# SF32LB52x register map
File version: 1.0
CPU: CM33 r0p1, little endian, MPU, FPU, 3 interrupt priority bits
Registers are 32-bit, read-write, reset 0x0 unless marked. A register's access mark holds for its fields unless they carry their own. Offsets are from the block's base; lines under a group give offsets from that group; [hi:lo] are bit positions; {n}, {i} and the like mark numbered series; 'fields as' and 'values as' point back to an identical list; <NAME> marks a mode.

## Memory map
0x40000000 LPSYS_RCC size 0x1000
0x40001000 DMAC2 size 0x1000
0x40003000 LPSYS_PINMUX size 0x1000
0x40005000 USART4 size 0x1000 — USART
0x40006000 USART5 size 0x1000 — USART
0x40009000 BTIM3 size 0x1000 — Basic Timer
0x4000A000 BTIM4 size 0x1000 — Basic Timer
0x4000B000 WDT2 size 0x1000 — Watchdog 2
0x4000C000 PTC2 size 0x1000
0x4000F000 LPSYS_CFG size 0x1000
0x40040000 LPSYS_AON size 0x1000
0x40042000 LPTIM3 size 0x1000 — Low Power Timer
0x40085000 CRC2 size 0x1000 — Cyclic Redundancy Check
0x50000000 HPSYS_RCC size 0x1000
0x50001000 EXTDMA size 0x1000
0x50003000 HPSYS_PINMUX size 0x1000
0x50004000 ATIM1 size 0x1000 — Advanced Timer
0x50005000 AUDPRC size 0x1000 — Audio Process Controller
0x50006000 EZIP1 size 0x1000
0x50007000 EPIC size 0x1000
0x50008000 LCDC1 size 0x1000 — LCD Controller
0x50009000 I2S1 size 0x1000 — Inter IC Sound
0x5000B000 HPSYS_CFG size 0x1000
0x5000C000 EFUSEC size 0x1000 — efuse control
0x5000D000 AES size 0x1000
0x5000F000 TRNG size 0x1000 — True Random Number Generator
0x50041000 MPI1 size 0x1000 — Memory Peripheral Interface
0x50042000 MPI2 size 0x1000 — Memory Peripheral Interface
0x50045000 SDMMC1 size 0x1000
0x50048000 CRC1 size 0x1000 — Cyclic Redundancy Check
0x50080000 PTC1 size 0x1000
0x50081000 DMAC1 size 0x1000
0x50084000 USART1 size 0x1000 — USART
0x50085000 USART2 size 0x1000 — USART
0x50086000 USART3 size 0x1000 — USART
0x50087000 GPADC size 0x1000
0x50088000 AUDCODEC size 0x1000
0x50089000 TSEN size 0x1000
0x50090000 GPTIM1 size 0x1000 — General Purpose Timer
0x50092000 BTIM1 size 0x1000 — Basic Timer
0x50094000 WDT1 size 0x1000 — Watchdog 1
0x50095000 SPI1 size 0x1000 — SPI
0x50096000 SPI2 size 0x1000 — SPI
0x5009A000 PDM1 size 0x1000 — Pulse Density Modulation
0x5009C000 I2C1 size 0x1000 — I2C
0x5009D000 I2C2 size 0x1000 — I2C
0x5009E000 I2C3 size 0x1000 — I2C
0x5009F000 I2C4 size 0x1000 — I2C
0x500A0000 HPSYS_GPIO size 0x1000
0x500B0000 GPTIM2 size 0x1000 — General Purpose Timer
0x500B1000 BTIM2 size 0x1000 — Basic Timer
0x500C0000 HPSYS_AON size 0x1000
0x500C1000 LPTIM1 size 0x1000 — Low Power Timer
0x500C2000 LPTIM2 size 0x1000 — Low Power Timer
0x500CA000 PMUC size 0x1000
0x500CC000 IWDT size 0x1000 — IWatchdog

## EXTDMA
Base 0x50001000
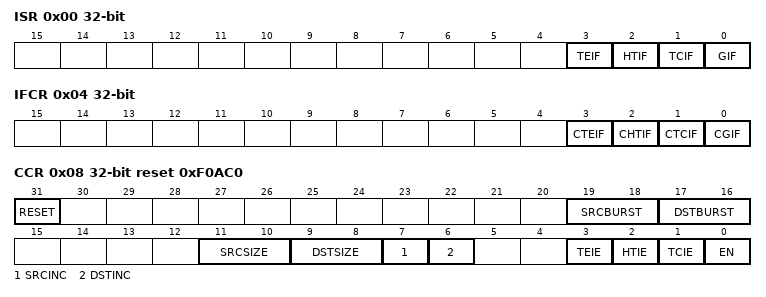
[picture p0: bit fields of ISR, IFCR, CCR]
0x00 ISR — interrupt status register
  [3] TEIF — TEIF, transfer error flag
  [2] HTIF — HTIF, half transfer flag
  [1] TCIF — TCIF, transfer complete flag
  [0] GIF — GIF, global interrupt flag
0x04 IFCR — interrupt clear register
  [3] CTEIF — CTEIF, transfer error flag clear
  [2] CHTIF — CHTIF, half transfer flag clear
  [1] CTCIF — CTCIF, transfer complete flag clear
  [0] CGIF — CGIF, global interrupt flag clear
0x08 CCR reset 0xF0AC0 — channel control register
  [31] RESET — Software reset, will clear extdma status. Active high. Will be cleared by HW automatically
  [19:18] SRCBURST — source burst transfer configuration 00: single transfer 01: INCR4 (incremental burst of 4 beats) 10: INCR8 (incremental burst of 8 beats) 11: INCR16 (incremental burst of 16 beats)
  [17:16] DSTBURST — destination burst transfer configuration 00: single transfer 01: INCR4 (incremental burst of 4 beats) 10: INCR8 (incremental burst of 8 beats) 11: INCR16 (incremental burst of 16 beats)
  [11:10] SRCSIZE — source size Defines the data size of each DMA transfer to the source memory. Should be fixed to 10 (32 bits), word access allowed only.
  [9:8] DSTSIZE — destination size Defines the data size of each DMA transfer to the destination memory. Should be fixed to 10 (32 bits), word access allowed only.
  [7] SRCINC — source increment mode Defines the increment mode for each DMA transfer to the source memory. 0: disabled 1: enabled
  [6] DSTINC — destination increment mode Defines the increment mode for each DMA transfer to the destination memory. 0: disabled 1: enabled
  [3] TEIE — transfer error interrupt enable 0: disabled 1: enabled
  [2] HTIE — half transfer interrupt enable 0: disabled 1: enabled
  [1] TCIE — transfer complete interrupt enable 0: disabled 1: enabled
  [0] EN — extdma enable. Will be cleared if ccr_reset is written
0x0C CNDTR — number of data register
  [19:0] NDT — number of data to transfer (0 to 2^20 - 1) This field is updated by hardware when the channel is enabled: It is decremented after each transfer, indicating the remaining amount of data items to transfer. It is kept at zero when the programmed amount of data to transfer is reached. If this field is zero, no transfer can be served whatever the channel enabled or not
0x10 SRCAR — source address register
  [31:0] SRCADDR — source address It contains the base address of the source data to be read. Should be word aligned
0x14 DSTAR — destination 0 address register
  [31:0] DSTADDR — destination address It contains the base address of the destination data to be written. Should be word aligned
